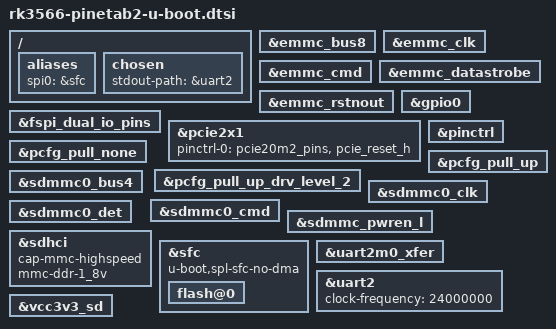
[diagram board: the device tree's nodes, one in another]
// SPDX-License-Identifier: GPL-2.0+

#include "rk356x-u-boot.dtsi"

/ {
	aliases {
		spi0 = &sfc;
	};

	chosen {
		stdout-path = &uart2;
	};
};

&emmc_bus8 {
	bootph-all;
};

&emmc_clk {
	bootph-all;
};

&emmc_cmd {
	bootph-all;
};

&emmc_datastrobe {
	bootph-all;
};

&emmc_rstnout {
	bootph-all;
};

&fspi_dual_io_pins {
	bootph-all;
};

&gpio0 {
	bootph-all;
};

&pcie2x1 {
	pinctrl-0 = <&pcie20m2_pins &pcie_reset_h>;
};

&pinctrl {
	bootph-all;
};

&pcfg_pull_none {
	bootph-all;
};

&pcfg_pull_up_drv_level_2 {
	bootph-all;
};

&pcfg_pull_up {
	bootph-all;
};

&sdmmc0_bus4 {
	bootph-all;
};

&sdmmc0_clk {
	bootph-all;
};

&sdmmc0_cmd {
	bootph-all;
};

&sdmmc0_det {
	bootph-all;
};

&sdmmc_pwren_l {
	bootph-all;
};

&sdhci {
	cap-mmc-highspeed;
	mmc-ddr-1_8v;
};

&sfc {
	bootph-pre-ram;
	u-boot,spl-sfc-no-dma;

	flash@0 {
		bootph-pre-ram;
	};
};

&uart2m0_xfer {
	bootph-all;
};

&uart2 {
	bootph-all;
	clock-frequency = <24000000>;
	status = "okay";
};

&vcc3v3_sd {
	bootph-pre-ram;
};
